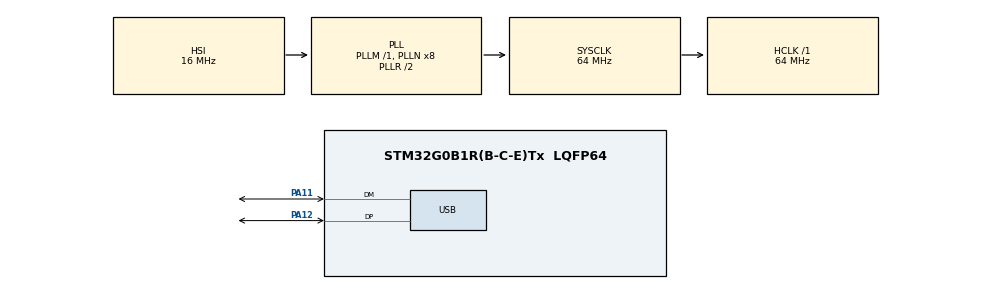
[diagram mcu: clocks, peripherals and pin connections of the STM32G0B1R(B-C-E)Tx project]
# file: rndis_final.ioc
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Mcu.Family=STM32G0
Mcu.Name=STM32G0B1R(B-C-E)Tx
Mcu.Package=LQFP64
NVIC.USB_UCPD1_2_IRQn=true\:0\:0\:false\:false\:true\:true\:true\:true
PA11\ [PA9].Mode=Device
PA11\ [PA9].Signal=USB_DM
PA12\ [PA10].Mode=Device
PA12\ [PA10].Signal=USB_DP
ProjectManager.HeapSize=0x200
ProjectManager.StackSize=0x400
ProjectManager.TargetToolchain=EWARM V8.50
RCC.ADCFreq_Value=64000000
RCC.AHBFreq_Value=64000000
RCC.CortexFreq_Value=64000000
RCC.EXTERNAL_CLOCK_VALUE=12288000
RCC.HCLKFreq_Value=64000000
RCC.HSE_VALUE=8000000
RCC.HSI48_VALUE=48000000
RCC.HSI_VALUE=16000000
RCC.SYSCLKFreq_VALUE=64000000
RCC.SYSCLKSource=RCC_SYSCLKSOURCE_PLLCLK
RCC.USBFreq_Value=48000000
RCC.VCOOutputFreq_Value=128000000
board=NUCLEO-G0B1RE

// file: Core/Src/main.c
/* USER CODE BEGIN Header */
/**
  ******************************************************************************
  * @file           : main.c
  * @brief          : Main program body
  ******************************************************************************
  * @attention
  *
  * Copyright (c) 2023 STMicroelectronics.
  * All rights reserved.
  *
  * This software is licensed under terms that can be found in the LICENSE file
  * in the root directory of this software component.
  * If no LICENSE file comes with this software, it is provided AS-IS.
  *
  ******************************************************************************
  */
/* USER CODE END Header */
#include "main.h"
//#include "usb_drd_fs.h"
#include "gpio.h"
#include "usb_device.h"
/* USER CODE BEGIN Includes */
#include "usbd_cdc_rndis_if.h"
/* USER CODE END Includes */

/* USER CODE BEGIN PV */
USBD_HandleTypeDef        USBD_Device;
struct netif              gnetif;
/* USER CODE END PV */

void SystemClock_Config(void);

int main(void)
{

  /* MCU Configuration--------------------------------------------------------*/

  /* Reset of all peripherals, Initializes the Flash interface and the Systick. */
  HAL_Init();

  /* Configure the system clock */
  SystemClock_Config();

  /* USER CODE BEGIN SysInit */
  MX_USB_Device_Init();

  /* USER CODE END SysInit */

  /* Initialize all configured peripherals */
  MX_GPIO_Init();
  /* USER CODE BEGIN 2 */
  //USBD_CDC_RNDIS_fops.Init();
  /* USER CODE END 2 */

  /* Infinite loop */
  while (1)
  {

  }
}

void SystemClock_Config(void)
{
  RCC_OscInitTypeDef RCC_OscInitStruct = {0};
  RCC_ClkInitTypeDef RCC_ClkInitStruct = {0};

  /** Configure the main internal regulator output voltage
  */
  HAL_PWREx_ControlVoltageScaling(PWR_REGULATOR_VOLTAGE_SCALE1);

  /** Initializes the RCC Oscillators according to the specified parameters
  * in the RCC_OscInitTypeDef structure.
  */
  RCC_OscInitStruct.OscillatorType = RCC_OSCILLATORTYPE_HSI|RCC_OSCILLATORTYPE_HSI48;
  RCC_OscInitStruct.HSIState = RCC_HSI_ON;
  RCC_OscInitStruct.HSI48State = RCC_HSI48_ON;
  RCC_OscInitStruct.HSIDiv = RCC_HSI_DIV1;
  RCC_OscInitStruct.HSICalibrationValue = RCC_HSICALIBRATION_DEFAULT;
  RCC_OscInitStruct.PLL.PLLState = RCC_PLL_ON;
  RCC_OscInitStruct.PLL.PLLSource = RCC_PLLSOURCE_HSI;
  RCC_OscInitStruct.PLL.PLLM = RCC_PLLM_DIV1;
  RCC_OscInitStruct.PLL.PLLN = 8;
  RCC_OscInitStruct.PLL.PLLP = RCC_PLLP_DIV2;
  RCC_OscInitStruct.PLL.PLLQ = RCC_PLLQ_DIV2;
  RCC_OscInitStruct.PLL.PLLR = RCC_PLLR_DIV2;
  if (HAL_RCC_OscConfig(&RCC_OscInitStruct) != HAL_OK)
  {
    Error_Handler();
  }
  /** Initializes the CPU, AHB and APB buses clocks
  */
  RCC_ClkInitStruct.ClockType = RCC_CLOCKTYPE_HCLK|RCC_CLOCKTYPE_SYSCLK
                              |RCC_CLOCKTYPE_PCLK1;
  RCC_ClkInitStruct.SYSCLKSource = RCC_SYSCLKSOURCE_PLLCLK;
  RCC_ClkInitStruct.AHBCLKDivider = RCC_SYSCLK_DIV1;
  RCC_ClkInitStruct.APB1CLKDivider = RCC_HCLK_DIV1;

  if (HAL_RCC_ClockConfig(&RCC_ClkInitStruct, FLASH_LATENCY_2) != HAL_OK)
  {
    Error_Handler();
  }
}

void Error_Handler(void)
{
  __disable_irq();
  while (1)
  {
  }
}
